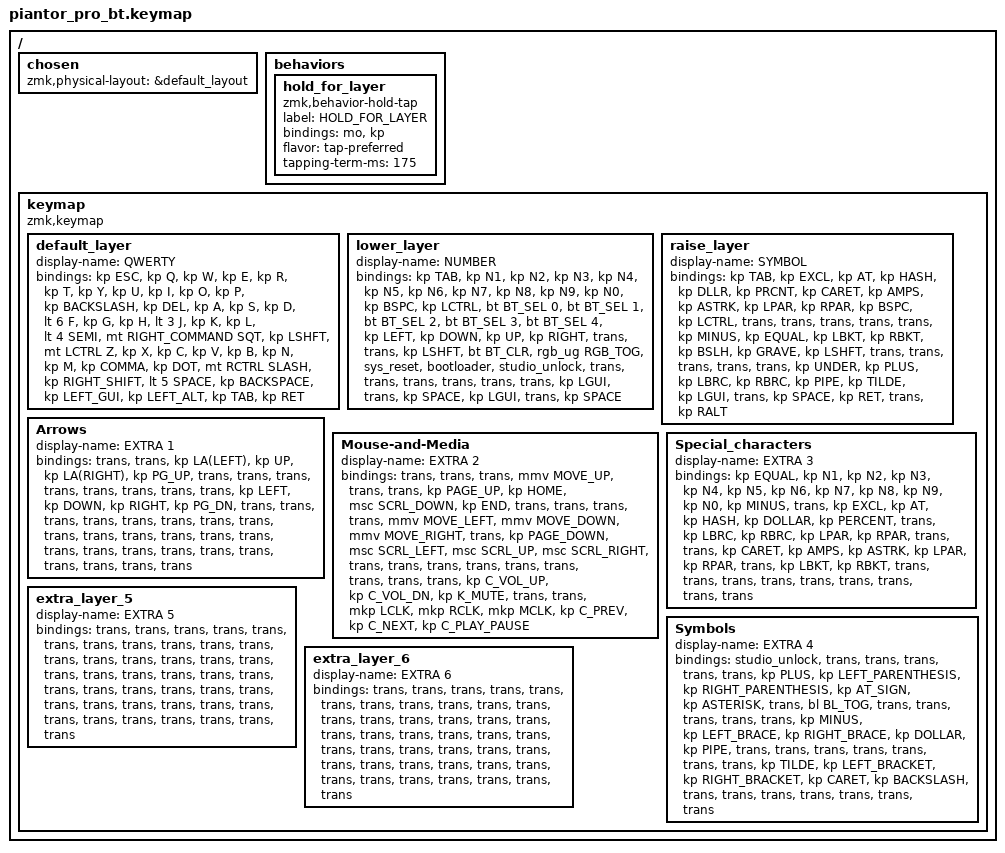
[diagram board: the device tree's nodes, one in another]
/*
 * Copyright (c) 2020 The ZMK Contributors
 *
 * SPDX-License-Identifier: MIT
 */

#include <behaviors.dtsi>
#include <dt-bindings/zmk/backlight.h>
#include <dt-bindings/zmk/bt.h>
#include <dt-bindings/zmk/keys.h>
#include <dt-bindings/zmk/pointing.h>
#include <dt-bindings/zmk/rgb.h>

/ {
    chosen { zmk,physical-layout = &default_layout; };
};

/ {
    behaviors {
        hold_for_layer: hold_for_layer {
            compatible = "zmk,behavior-hold-tap";
            label = "HOLD_FOR_LAYER";
            bindings = <&mo>, <&kp>;

            #binding-cells = <2>;
            flavor = "tap-preferred";
            tapping-term-ms = <175>;
        };
    };

    keymap {
        compatible = "zmk,keymap";

        default_layer {
            display-name = "QWERTY";

            // --------------------------------------------------------------------------------
            // |  TAB |  Q  |  W  |  E  |  R  |  T  |  Y  |  U   |  I  |  O  |  P  | BSPC |
            // | CTRL |  A  |  S  |  D  |  F  |  G  |  H  |  J   |  K  |  L  |  ;  |  '   |
            // | SHFT |  Z  |  X  |  C  |  V  |  B  |  N  |  M   |  ,  |  .  |  /  | ESC  |
            //                    | GUI | LWR | SPC | ENT | RSE  | ALT |

            bindings = <
&kp ESC  &kp Q  &kp W  &kp E  &kp R  &kp T  &kp Y  &kp U  &kp I  &kp O  &kp P  &kp BACKSLASH  &kp DEL  &kp A  &kp S  &kp D  &lt 6 F  &kp G  &kp H  &lt 3 J  &kp K  &kp L  &lt 4 SEMI  &mt RIGHT_COMMAND SQT  &kp LSHFT  &mt LCTRL Z  &kp X  &kp C  &kp V  &kp B  &kp N  &kp M  &kp COMMA  &kp DOT  &mt RCTRL SLASH  &kp RIGHT_SHIFT  &lt 5 SPACE  &kp BACKSPACE  &kp LEFT_GUI  &kp LEFT_ALT  &kp TAB  &kp RET
            >;
        };

        lower_layer {
            display-name = "NUMBER";

            // -----------------------------------------------------------------------------------------
            // |  TAB |  1  |  2  |  3  |  4  |  5    |  6  |  7  |  8  |  9  |  0  | BSPC |
            // | CTRL | BT1 | BT2 | BT3 | BT4 | BT5   | LFT | DWN |  UP | RGT |     |      |
            // | SHFT | BTCR| RGB | RST | BOOT| Unlock|     |     |     |     |     |      |
            //                    | GUI |     | SPC   | ENT |     | ALT |

            bindings = <
&kp TAB  &kp N1  &kp N2  &kp N3  &kp N4  &kp N5  &kp N6  &kp N7  &kp N8  &kp N9  &kp N0  &kp BSPC  &kp LCTRL  &bt BT_SEL 0  &bt BT_SEL 1  &bt BT_SEL 2  &bt BT_SEL 3  &bt BT_SEL 4  &kp LEFT  &kp DOWN  &kp UP  &kp RIGHT  &trans  &trans  &kp LSHFT  &bt BT_CLR  &rgb_ug RGB_TOG  &sys_reset  &bootloader  &studio_unlock  &trans  &trans  &trans  &trans  &trans  &trans  &kp LGUI  &trans  &kp SPACE  &kp LGUI  &trans  &kp SPACE
            >;
        };

        raise_layer {
            display-name = "SYMBOL";

            // -----------------------------------------------------------------------------------------
            // |  TAB |  !  |  @  |  #  |  $  |  %  |  ^  |  &  |  *  |  (  |  )  | BSPC |
            // | CTRL |     |     |     |     |     |  -  |  =  |  [  |  ]  |  \  |  `   |
            // | SHFT |     |     |     |     |     |  _  |  +  |  {  |  }  | "|" |  ~   |
            //                    | GUI |     | SPC | ENT |     | ALT |

            bindings = <
&kp TAB  &kp EXCL  &kp AT  &kp HASH  &kp DLLR  &kp PRCNT  &kp CARET  &kp AMPS  &kp ASTRK  &kp LPAR  &kp RPAR  &kp BSPC  &kp LCTRL  &trans  &trans  &trans  &trans  &trans  &kp MINUS  &kp EQUAL  &kp LBKT  &kp RBKT  &kp BSLH  &kp GRAVE  &kp LSHFT  &trans  &trans  &trans  &trans  &trans  &kp UNDER  &kp PLUS  &kp LBRC  &kp RBRC  &kp PIPE  &kp TILDE  &kp LGUI  &trans  &kp SPACE  &kp RET  &trans  &kp RALT
            >;
        };

        Arrows {
            display-name = "EXTRA 1";
            bindings = <
&trans  &trans  &kp LA(LEFT)  &kp UP  &kp LA(RIGHT)  &kp PG_UP  &trans  &trans  &trans  &trans  &trans  &trans  &trans  &trans  &kp LEFT  &kp DOWN  &kp RIGHT  &kp PG_DN  &trans  &trans  &trans  &trans  &trans  &trans  &trans  &trans  &trans  &trans  &trans  &trans  &trans  &trans  &trans  &trans  &trans  &trans  &trans  &trans  &trans  &trans  &trans  &trans
            >;
        };

        Mouse-and-Media {
            display-name = "EXTRA 2";
            bindings = <
&trans  &trans  &trans  &mmv MOVE_UP  &trans  &trans  &kp PAGE_UP  &kp HOME  &msc SCRL_DOWN  &kp END  &trans  &trans  &trans  &trans  &mmv MOVE_LEFT  &mmv MOVE_DOWN  &mmv MOVE_RIGHT  &trans  &kp PAGE_DOWN  &msc SCRL_LEFT  &msc SCRL_UP  &msc SCRL_RIGHT  &trans  &trans  &trans  &trans  &trans  &trans  &trans  &trans  &trans  &kp C_VOL_UP  &kp C_VOL_DN  &kp K_MUTE  &trans  &trans  &mkp LCLK  &mkp RCLK  &mkp MCLK  &kp C_PREV  &kp C_NEXT  &kp C_PLAY_PAUSE
            >;
        };

        Special_characters {
            display-name = "EXTRA 3";
            bindings = <
&kp EQUAL  &kp N1  &kp N2  &kp N3  &kp N4  &kp N5  &kp N6  &kp N7  &kp N8  &kp N9  &kp N0  &kp MINUS  &trans  &kp EXCL  &kp AT  &kp HASH  &kp DOLLAR  &kp PERCENT  &trans  &kp LBRC  &kp RBRC  &kp LPAR  &kp RPAR  &trans  &trans  &kp CARET  &kp AMPS  &kp ASTRK  &kp LPAR  &kp RPAR  &trans  &kp LBKT  &kp RBKT  &trans  &trans  &trans  &trans  &trans  &trans  &trans  &trans  &trans
            >;
        };

        Symbols {
            display-name = "EXTRA 4";
            bindings = <
&studio_unlock  &trans  &trans  &trans  &trans  &trans  &kp PLUS  &kp LEFT_PARENTHESIS  &kp RIGHT_PARENTHESIS  &kp AT_SIGN  &kp ASTERISK  &trans  &bl BL_TOG  &trans  &trans  &trans  &trans  &trans  &kp MINUS  &kp LEFT_BRACE  &kp RIGHT_BRACE  &kp DOLLAR  &kp PIPE  &trans  &trans  &trans  &trans  &trans  &trans  &trans  &kp TILDE  &kp LEFT_BRACKET  &kp RIGHT_BRACKET  &kp CARET  &kp BACKSLASH  &trans  &trans  &trans  &trans  &trans  &trans  &trans
            >;
        };

        extra_layer_5 {
            display-name = "EXTRA 5";
            bindings = <
&trans  &trans  &trans  &trans  &trans  &trans  &trans  &trans  &trans  &trans  &trans  &trans  &trans  &trans  &trans  &trans  &trans  &trans  &trans  &trans  &trans  &trans  &trans  &trans  &trans  &trans  &trans  &trans  &trans  &trans  &trans  &trans  &trans  &trans  &trans  &trans  &trans  &trans  &trans  &trans  &trans  &trans
            >;
        };

        extra_layer_6 {
            display-name = "EXTRA 6";
            bindings = <
&trans  &trans  &trans  &trans  &trans  &trans  &trans  &trans  &trans  &trans  &trans  &trans  &trans  &trans  &trans  &trans  &trans  &trans  &trans  &trans  &trans  &trans  &trans  &trans  &trans  &trans  &trans  &trans  &trans  &trans  &trans  &trans  &trans  &trans  &trans  &trans  &trans  &trans  &trans  &trans  &trans  &trans
            >;
        };
    };
};
